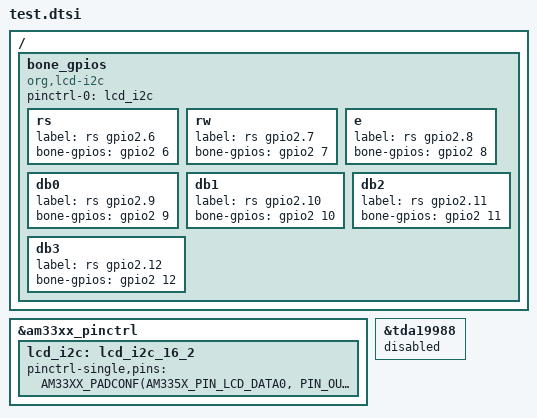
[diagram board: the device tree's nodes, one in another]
/ {
	bone_gpios {
		compatible = "org,lcd-i2c";
		pinctrl-names = "default";
		pinctrl-0 = <&lcd_i2c>;

		rs {
			label = "rs gpio2.6";
			bone-gpios = <&gpio2 6 GPIO_ACTIVE_HIGH>;
		};
		rw {
			label = "rs gpio2.7";
			bone-gpios = <&gpio2 7 GPIO_ACTIVE_HIGH>;
		};
		e {
			label = "rs gpio2.8";
			bone-gpios = <&gpio2 8 GPIO_ACTIVE_HIGH>;
		};
		db0 {
			label = "rs gpio2.9";
			bone-gpios = <&gpio2 9 GPIO_ACTIVE_HIGH>;
		};
		db1 {
			label = "rs gpio2.10";
			bone-gpios = <&gpio2 10 GPIO_ACTIVE_HIGH>;
		};
		db2 {
			label = "rs gpio2.11";
			bone-gpios = <&gpio2 11 GPIO_ACTIVE_HIGH>;
		};
		db3 {
			label = "rs gpio2.12";
			bone-gpios = <&gpio2 12 GPIO_ACTIVE_HIGH>;
		};
	};
};

&am33xx_pinctrl {
	lcd_i2c: lcd_i2c_16_2 {
		pinctrl-single,pins = <
			AM33XX_PADCONF(AM335X_PIN_LCD_DATA0, PIN_OUTPUT, MUX_MODE7)
			AM33XX_PADCONF(AM335X_PIN_LCD_DATA1, PIN_OUTPUT, MUX_MODE7)
			AM33XX_PADCONF(AM335X_PIN_LCD_DATA2, PIN_OUTPUT, MUX_MODE7)
			AM33XX_PADCONF(AM335X_PIN_LCD_DATA3, PIN_OUTPUT, MUX_MODE7)
			AM33XX_PADCONF(AM335X_PIN_LCD_DATA4, PIN_OUTPUT, MUX_MODE7)
			AM33XX_PADCONF(AM335X_PIN_LCD_DATA5, PIN_OUTPUT, MUX_MODE7)
			AM33XX_PADCONF(AM335X_PIN_LCD_DATA6, PIN_OUTPUT, MUX_MODE7)
		>;
	};
};

&tda19988 {
	status = "disabled";
};
